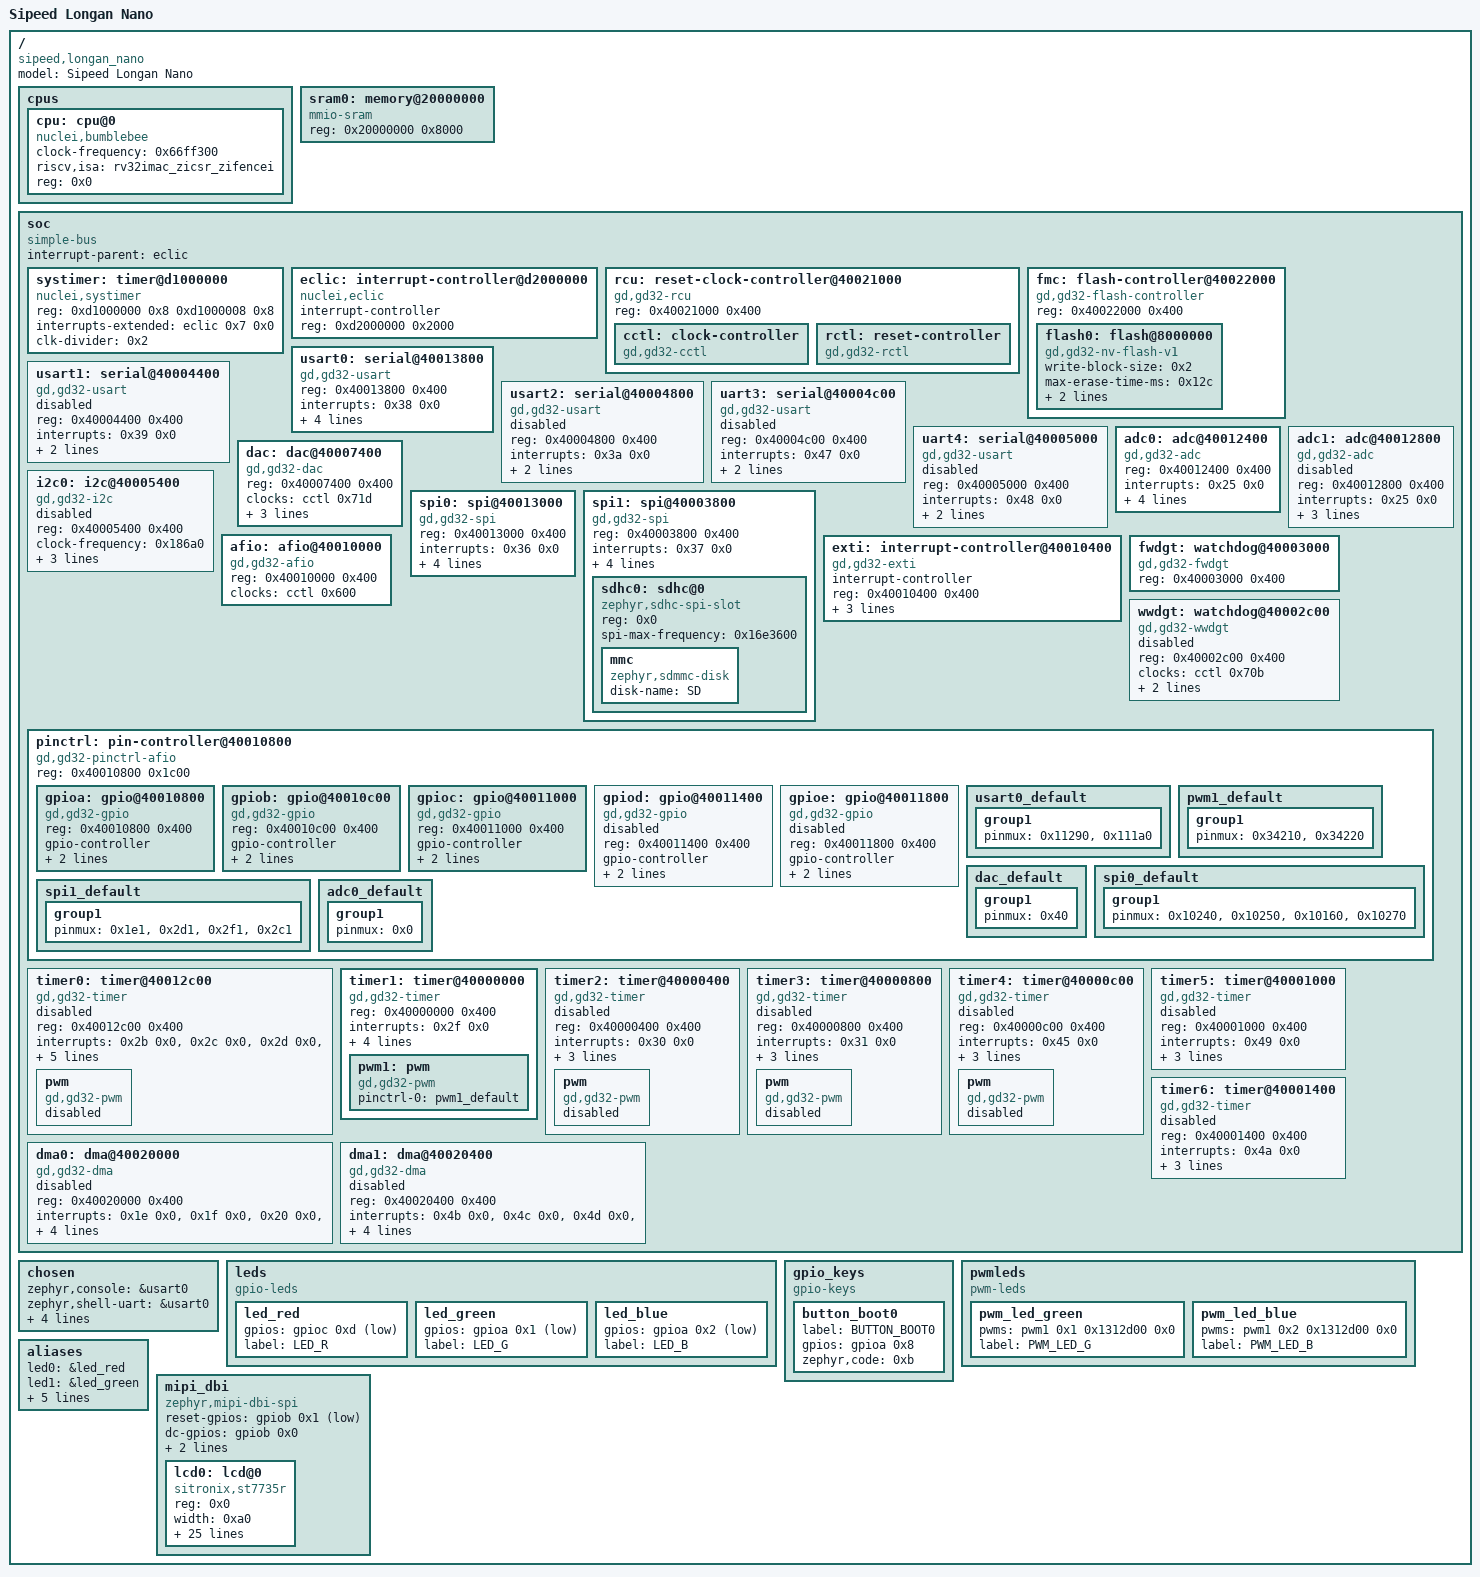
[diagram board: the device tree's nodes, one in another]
/dts-v1/;

/* node '/' defined in zephyr/dts/riscv/gd/gd32vf103.dtsi:16 */
/ {
	#address-cells = < 0x1 >;          /* in zephyr/dts/riscv/gd/gd32vf103.dtsi:17 */
	#size-cells = < 0x1 >;             /* in zephyr/dts/riscv/gd/gd32vf103.dtsi:18 */
	model = "Sipeed Longan Nano";      /* in zephyr/boards/sipeed/longan_nano/longan_nano.dts:13 */
	compatible = "sipeed,longan_nano"; /* in zephyr/boards/sipeed/longan_nano/longan_nano.dts:14 */

	/* node '/cpus' defined in zephyr/dts/riscv/gd/gd32vf103.dtsi:20 */
	cpus {
		#address-cells = < 0x1 >; /* in zephyr/dts/riscv/gd/gd32vf103.dtsi:21 */
		#size-cells = < 0x0 >;    /* in zephyr/dts/riscv/gd/gd32vf103.dtsi:22 */

		/* node '/cpus/cpu@0' defined in zephyr/dts/riscv/gd/gd32vf103.dtsi:24 */
		cpu: cpu@0 {
			clock-frequency = < 0x66ff300 >;       /* in zephyr/dts/riscv/gd/gd32vf103.dtsi:25 */
			compatible = "nuclei,bumblebee",
			             "riscv";                  /* in zephyr/dts/riscv/gd/gd32vf103.dtsi:26 */
			riscv,isa = "rv32imac_zicsr_zifencei"; /* in zephyr/dts/riscv/gd/gd32vf103.dtsi:27 */
			reg = < 0x0 >;                         /* in zephyr/dts/riscv/gd/gd32vf103.dtsi:28 */
		};
	};

	/* node '/memory@20000000' defined in zephyr/dts/riscv/gd/gd32vf103.dtsi:32 */
	sram0: memory@20000000 {
		compatible = "mmio-sram";    /* in zephyr/dts/riscv/gd/gd32vf103.dtsi:33 */
		reg = < 0x20000000 0x8000 >; /* in zephyr/dts/riscv/gd/gd32vf103Xb.dtsi:11 */
	};

	/* node '/soc' defined in zephyr/dts/riscv/gd/gd32vf103.dtsi:36 */
	soc {
		#address-cells = < 0x1 >;      /* in zephyr/dts/riscv/gd/gd32vf103.dtsi:37 */
		#size-cells = < 0x1 >;         /* in zephyr/dts/riscv/gd/gd32vf103.dtsi:38 */
		compatible = "simple-bus";     /* in zephyr/dts/riscv/gd/gd32vf103.dtsi:39 */
		interrupt-parent = < &eclic >; /* in zephyr/dts/riscv/gd/gd32vf103.dtsi:40 */
		ranges;                        /* in zephyr/dts/riscv/gd/gd32vf103.dtsi:41 */

		/* node '/soc/timer@d1000000' defined in zephyr/dts/riscv/gd/gd32vf103.dtsi:43 */
		systimer: timer@d1000000 {
			compatible = "nuclei,systimer",
			             "riscv,machine-timer";       /* in zephyr/dts/riscv/gd/gd32vf103.dtsi:44 */
			reg = < 0xd1000000 0x8 0xd1000008 0x8 >;  /* in zephyr/dts/riscv/gd/gd32vf103.dtsi:45 */
			reg-names = "mtime",
			            "mtimecmp";                   /* in zephyr/dts/riscv/gd/gd32vf103.dtsi:46 */
			interrupts-extended = < &eclic 0x7 0x0 >; /* in zephyr/dts/riscv/gd/gd32vf103.dtsi:47 */
			clk-divider = < 0x2 >;                    /* in zephyr/dts/riscv/gd/gd32vf103.dtsi:48 */
		};

		/* node '/soc/interrupt-controller@d2000000' defined in zephyr/dts/riscv/gd/gd32vf103.dtsi:51 */
		eclic: interrupt-controller@d2000000 {
			compatible = "nuclei,eclic"; /* in zephyr/dts/riscv/gd/gd32vf103.dtsi:52 */
			#address-cells = < 0x0 >;    /* in zephyr/dts/riscv/gd/gd32vf103.dtsi:53 */
			#interrupt-cells = < 0x2 >;  /* in zephyr/dts/riscv/gd/gd32vf103.dtsi:54 */
			interrupt-controller;        /* in zephyr/dts/riscv/gd/gd32vf103.dtsi:55 */
			reg = < 0xd2000000 0x2000 >; /* in zephyr/dts/riscv/gd/gd32vf103.dtsi:56 */
			phandle = < 0x1 >;           /* in zephyr/dts/riscv/gd/gd32vf103.dtsi:40 */
		};

		/* node '/soc/reset-clock-controller@40021000' defined in zephyr/dts/riscv/gd/gd32vf103.dtsi:59 */
		rcu: reset-clock-controller@40021000 {
			compatible = "gd,gd32-rcu"; /* in zephyr/dts/riscv/gd/gd32vf103.dtsi:60 */
			reg = < 0x40021000 0x400 >; /* in zephyr/dts/riscv/gd/gd32vf103.dtsi:61 */
			status = "okay";            /* in zephyr/dts/riscv/gd/gd32vf103.dtsi:62 */

			/* node '/soc/reset-clock-controller@40021000/clock-controller' defined in zephyr/dts/riscv/gd/gd32vf103.dtsi:64 */
			cctl: clock-controller {
				compatible = "gd,gd32-cctl"; /* in zephyr/dts/riscv/gd/gd32vf103.dtsi:65 */
				#clock-cells = < 0x1 >;      /* in zephyr/dts/riscv/gd/gd32vf103.dtsi:66 */
				status = "okay";             /* in zephyr/dts/riscv/gd/gd32vf103.dtsi:67 */
				phandle = < 0x2 >;           /* in zephyr/dts/riscv/gd/gd32vf103.dtsi:95 */
			};

			/* node '/soc/reset-clock-controller@40021000/reset-controller' defined in zephyr/dts/riscv/gd/gd32vf103.dtsi:70 */
			rctl: reset-controller {
				compatible = "gd,gd32-rctl"; /* in zephyr/dts/riscv/gd/gd32vf103.dtsi:71 */
				#reset-cells = < 0x1 >;      /* in zephyr/dts/riscv/gd/gd32vf103.dtsi:72 */
				status = "okay";             /* in zephyr/dts/riscv/gd/gd32vf103.dtsi:73 */
				phandle = < 0x3 >;           /* in zephyr/dts/riscv/gd/gd32vf103.dtsi:96 */
			};
		};

		/* node '/soc/flash-controller@40022000' defined in zephyr/dts/riscv/gd/gd32vf103.dtsi:77 */
		fmc: flash-controller@40022000 {
			compatible = "gd,gd32-flash-controller"; /* in zephyr/dts/riscv/gd/gd32vf103.dtsi:78 */
			reg = < 0x40022000 0x400 >;              /* in zephyr/dts/riscv/gd/gd32vf103.dtsi:79 */
			#address-cells = < 0x1 >;                /* in zephyr/dts/riscv/gd/gd32vf103.dtsi:80 */
			#size-cells = < 0x1 >;                   /* in zephyr/dts/riscv/gd/gd32vf103.dtsi:81 */

			/* node '/soc/flash-controller@40022000/flash@8000000' defined in zephyr/dts/riscv/gd/gd32vf103.dtsi:83 */
			flash0: flash@8000000 {
				compatible = "gd,gd32-nv-flash-v1",
				             "soc-nv-flash";        /* in zephyr/dts/riscv/gd/gd32vf103.dtsi:84 */
				write-block-size = < 0x2 >;         /* in zephyr/dts/riscv/gd/gd32vf103.dtsi:85 */
				max-erase-time-ms = < 0x12c >;      /* in zephyr/dts/riscv/gd/gd32vf103.dtsi:86 */
				page-size = < 0x400 >;              /* in zephyr/dts/riscv/gd/gd32vf103.dtsi:87 */
				reg = < 0x8000000 0x20000 >;        /* in zephyr/dts/riscv/gd/gd32vf103Xb.dtsi:15 */
			};
		};

		/* node '/soc/serial@40013800' defined in zephyr/dts/riscv/gd/gd32vf103.dtsi:91 */
		usart0: serial@40013800 {
			compatible = "gd,gd32-usart";    /* in zephyr/dts/riscv/gd/gd32vf103.dtsi:92 */
			reg = < 0x40013800 0x400 >;      /* in zephyr/dts/riscv/gd/gd32vf103.dtsi:93 */
			interrupts = < 0x38 0x0 >;       /* in zephyr/dts/riscv/gd/gd32vf103.dtsi:94 */
			clocks = < &cctl 0x60e >;        /* in zephyr/dts/riscv/gd/gd32vf103.dtsi:95 */
			resets = < &rctl 0x30e >;        /* in zephyr/dts/riscv/gd/gd32vf103.dtsi:96 */
			status = "okay";                 /* in zephyr/boards/sipeed/longan_nano/longan_nano-common.dtsi:133 */
			current-speed = < 0x1c200 >;     /* in zephyr/boards/sipeed/longan_nano/longan_nano-common.dtsi:134 */
			pinctrl-0 = < &usart0_default >; /* in zephyr/boards/sipeed/longan_nano/longan_nano-common.dtsi:135 */
			pinctrl-names = "default";       /* in zephyr/boards/sipeed/longan_nano/longan_nano-common.dtsi:136 */
		};

		/* node '/soc/serial@40004400' defined in zephyr/dts/riscv/gd/gd32vf103.dtsi:100 */
		usart1: serial@40004400 {
			compatible = "gd,gd32-usart"; /* in zephyr/dts/riscv/gd/gd32vf103.dtsi:101 */
			reg = < 0x40004400 0x400 >;   /* in zephyr/dts/riscv/gd/gd32vf103.dtsi:102 */
			interrupts = < 0x39 0x0 >;    /* in zephyr/dts/riscv/gd/gd32vf103.dtsi:103 */
			clocks = < &cctl 0x711 >;     /* in zephyr/dts/riscv/gd/gd32vf103.dtsi:104 */
			resets = < &rctl 0x411 >;     /* in zephyr/dts/riscv/gd/gd32vf103.dtsi:105 */
			status = "disabled";          /* in zephyr/dts/riscv/gd/gd32vf103.dtsi:106 */
		};

		/* node '/soc/serial@40004800' defined in zephyr/dts/riscv/gd/gd32vf103.dtsi:109 */
		usart2: serial@40004800 {
			compatible = "gd,gd32-usart"; /* in zephyr/dts/riscv/gd/gd32vf103.dtsi:110 */
			reg = < 0x40004800 0x400 >;   /* in zephyr/dts/riscv/gd/gd32vf103.dtsi:111 */
			interrupts = < 0x3a 0x0 >;    /* in zephyr/dts/riscv/gd/gd32vf103.dtsi:112 */
			clocks = < &cctl 0x712 >;     /* in zephyr/dts/riscv/gd/gd32vf103.dtsi:113 */
			resets = < &rctl 0x412 >;     /* in zephyr/dts/riscv/gd/gd32vf103.dtsi:114 */
			status = "disabled";          /* in zephyr/dts/riscv/gd/gd32vf103.dtsi:115 */
		};

		/* node '/soc/serial@40004c00' defined in zephyr/dts/riscv/gd/gd32vf103.dtsi:118 */
		uart3: serial@40004c00 {
			compatible = "gd,gd32-usart"; /* in zephyr/dts/riscv/gd/gd32vf103.dtsi:119 */
			reg = < 0x40004c00 0x400 >;   /* in zephyr/dts/riscv/gd/gd32vf103.dtsi:120 */
			interrupts = < 0x47 0x0 >;    /* in zephyr/dts/riscv/gd/gd32vf103.dtsi:121 */
			clocks = < &cctl 0x713 >;     /* in zephyr/dts/riscv/gd/gd32vf103.dtsi:122 */
			resets = < &rctl 0x413 >;     /* in zephyr/dts/riscv/gd/gd32vf103.dtsi:123 */
			status = "disabled";          /* in zephyr/dts/riscv/gd/gd32vf103.dtsi:124 */
		};

		/* node '/soc/serial@40005000' defined in zephyr/dts/riscv/gd/gd32vf103.dtsi:127 */
		uart4: serial@40005000 {
			compatible = "gd,gd32-usart"; /* in zephyr/dts/riscv/gd/gd32vf103.dtsi:128 */
			reg = < 0x40005000 0x400 >;   /* in zephyr/dts/riscv/gd/gd32vf103.dtsi:129 */
			interrupts = < 0x48 0x0 >;    /* in zephyr/dts/riscv/gd/gd32vf103.dtsi:130 */
			clocks = < &cctl 0x714 >;     /* in zephyr/dts/riscv/gd/gd32vf103.dtsi:131 */
			resets = < &rctl 0x414 >;     /* in zephyr/dts/riscv/gd/gd32vf103.dtsi:132 */
			status = "disabled";          /* in zephyr/dts/riscv/gd/gd32vf103.dtsi:133 */
		};

		/* node '/soc/adc@40012400' defined in zephyr/dts/riscv/gd/gd32vf103.dtsi:136 */
		adc0: adc@40012400 {
			compatible = "gd,gd32-adc";    /* in zephyr/dts/riscv/gd/gd32vf103.dtsi:137 */
			reg = < 0x40012400 0x400 >;    /* in zephyr/dts/riscv/gd/gd32vf103.dtsi:138 */
			interrupts = < 0x25 0x0 >;     /* in zephyr/dts/riscv/gd/gd32vf103.dtsi:139 */
			clocks = < &cctl 0x609 >;      /* in zephyr/dts/riscv/gd/gd32vf103.dtsi:140 */
			resets = < &rctl 0x309 >;      /* in zephyr/dts/riscv/gd/gd32vf103.dtsi:141 */
			channels = < 0x10 >;           /* in zephyr/dts/riscv/gd/gd32vf103.dtsi:142 */
			#io-channel-cells = < 0x1 >;   /* in zephyr/dts/riscv/gd/gd32vf103.dtsi:144 */
			status = "okay";               /* in zephyr/boards/sipeed/longan_nano/longan_nano-common.dtsi:186 */
			pinctrl-0 = < &adc0_default >; /* in zephyr/boards/sipeed/longan_nano/longan_nano-common.dtsi:187 */
			pinctrl-names = "default";     /* in zephyr/boards/sipeed/longan_nano/longan_nano-common.dtsi:188 */
		};

		/* node '/soc/adc@40012800' defined in zephyr/dts/riscv/gd/gd32vf103.dtsi:147 */
		adc1: adc@40012800 {
			compatible = "gd,gd32-adc";  /* in zephyr/dts/riscv/gd/gd32vf103.dtsi:148 */
			reg = < 0x40012800 0x400 >;  /* in zephyr/dts/riscv/gd/gd32vf103.dtsi:149 */
			interrupts = < 0x25 0x0 >;   /* in zephyr/dts/riscv/gd/gd32vf103.dtsi:150 */
			clocks = < &cctl 0x60a >;    /* in zephyr/dts/riscv/gd/gd32vf103.dtsi:151 */
			resets = < &rctl 0x30a >;    /* in zephyr/dts/riscv/gd/gd32vf103.dtsi:152 */
			channels = < 0x10 >;         /* in zephyr/dts/riscv/gd/gd32vf103.dtsi:153 */
			status = "disabled";         /* in zephyr/dts/riscv/gd/gd32vf103.dtsi:154 */
			#io-channel-cells = < 0x1 >; /* in zephyr/dts/riscv/gd/gd32vf103.dtsi:155 */
		};

		/* node '/soc/dac@40007400' defined in zephyr/dts/riscv/gd/gd32vf103.dtsi:158 */
		dac: dac@40007400 {
			compatible = "gd,gd32-dac";   /* in zephyr/dts/riscv/gd/gd32vf103.dtsi:159 */
			reg = < 0x40007400 0x400 >;   /* in zephyr/dts/riscv/gd/gd32vf103.dtsi:160 */
			clocks = < &cctl 0x71d >;     /* in zephyr/dts/riscv/gd/gd32vf103.dtsi:161 */
			resets = < &rctl 0x41d >;     /* in zephyr/dts/riscv/gd/gd32vf103.dtsi:162 */
			num-channels = < 0x2 >;       /* in zephyr/dts/riscv/gd/gd32vf103.dtsi:163 */
			#io-channel-cells = < 0x1 >;  /* in zephyr/dts/riscv/gd/gd32vf103.dtsi:165 */
			status = "okay";              /* in zephyr/boards/sipeed/longan_nano/longan_nano-common.dtsi:151 */
			pinctrl-0 = < &dac_default >; /* in zephyr/boards/sipeed/longan_nano/longan_nano-common.dtsi:152 */
			pinctrl-names = "default";    /* in zephyr/boards/sipeed/longan_nano/longan_nano-common.dtsi:153 */
		};

		/* node '/soc/i2c@40005400' defined in zephyr/dts/riscv/gd/gd32vf103.dtsi:168 */
		i2c0: i2c@40005400 {
			compatible = "gd,gd32-i2c";    /* in zephyr/dts/riscv/gd/gd32vf103.dtsi:169 */
			reg = < 0x40005400 0x400 >;    /* in zephyr/dts/riscv/gd/gd32vf103.dtsi:170 */
			#address-cells = < 0x1 >;      /* in zephyr/dts/riscv/gd/gd32vf103.dtsi:171 */
			#size-cells = < 0x0 >;         /* in zephyr/dts/riscv/gd/gd32vf103.dtsi:172 */
			clock-frequency = < 0x186a0 >; /* in zephyr/dts/riscv/gd/gd32vf103.dtsi:173 */
			interrupts = < 0x32 0x0 >,
			             < 0x33 0x0 >;     /* in zephyr/dts/riscv/gd/gd32vf103.dtsi:174 */
			interrupt-names = "event",
			                  "error";     /* in zephyr/dts/riscv/gd/gd32vf103.dtsi:175 */
			clocks = < &cctl 0x715 >;      /* in zephyr/dts/riscv/gd/gd32vf103.dtsi:176 */
			resets = < &rctl 0x415 >;      /* in zephyr/dts/riscv/gd/gd32vf103.dtsi:177 */
			status = "disabled";           /* in zephyr/dts/riscv/gd/gd32vf103.dtsi:178 */
		};

		/* node '/soc/spi@40013000' defined in zephyr/dts/riscv/gd/gd32vf103.dtsi:181 */
		spi0: spi@40013000 {
			compatible = "gd,gd32-spi";    /* in zephyr/dts/riscv/gd/gd32vf103.dtsi:182 */
			reg = < 0x40013000 0x400 >;    /* in zephyr/dts/riscv/gd/gd32vf103.dtsi:183 */
			interrupts = < 0x36 0x0 >;     /* in zephyr/dts/riscv/gd/gd32vf103.dtsi:184 */
			clocks = < &cctl 0x60c >;      /* in zephyr/dts/riscv/gd/gd32vf103.dtsi:185 */
			resets = < &rctl 0x30c >;      /* in zephyr/dts/riscv/gd/gd32vf103.dtsi:186 */
			#address-cells = < 0x1 >;      /* in zephyr/dts/riscv/gd/gd32vf103.dtsi:188 */
			#size-cells = < 0x0 >;         /* in zephyr/dts/riscv/gd/gd32vf103.dtsi:189 */
			status = "okay";               /* in zephyr/boards/sipeed/longan_nano/longan_nano-common.dtsi:157 */
			pinctrl-0 = < &spi0_default >; /* in zephyr/boards/sipeed/longan_nano/longan_nano-common.dtsi:158 */
			pinctrl-names = "default";     /* in zephyr/boards/sipeed/longan_nano/longan_nano-common.dtsi:159 */
			cs-gpios = < &gpiob 0x2 0x1 >; /* in zephyr/boards/sipeed/longan_nano/longan_nano-common.dtsi:161 */
			phandle = < 0xe >;             /* in zephyr/boards/sipeed/longan_nano/longan_nano-common.dtsi:79 */
		};

		/* node '/soc/spi@40003800' defined in zephyr/dts/riscv/gd/gd32vf103.dtsi:192 */
		spi1: spi@40003800 {
			compatible = "gd,gd32-spi";    /* in zephyr/dts/riscv/gd/gd32vf103.dtsi:193 */
			reg = < 0x40003800 0x400 >;    /* in zephyr/dts/riscv/gd/gd32vf103.dtsi:194 */
			interrupts = < 0x37 0x0 >;     /* in zephyr/dts/riscv/gd/gd32vf103.dtsi:195 */
			clocks = < &cctl 0x70e >;      /* in zephyr/dts/riscv/gd/gd32vf103.dtsi:196 */
			resets = < &rctl 0x40e >;      /* in zephyr/dts/riscv/gd/gd32vf103.dtsi:197 */
			#address-cells = < 0x1 >;      /* in zephyr/dts/riscv/gd/gd32vf103.dtsi:199 */
			#size-cells = < 0x0 >;         /* in zephyr/dts/riscv/gd/gd32vf103.dtsi:200 */
			status = "okay";               /* in zephyr/boards/sipeed/longan_nano/longan_nano-common.dtsi:165 */
			pinctrl-0 = < &spi1_default >; /* in zephyr/boards/sipeed/longan_nano/longan_nano-common.dtsi:166 */
			pinctrl-names = "default";     /* in zephyr/boards/sipeed/longan_nano/longan_nano-common.dtsi:167 */
			cs-gpios = < &gpiob 0xc 0x1 >; /* in zephyr/boards/sipeed/longan_nano/longan_nano-common.dtsi:169 */

			/* node '/soc/spi@40003800/sdhc@0' defined in zephyr/boards/sipeed/longan_nano/longan_nano-common.dtsi:171 */
			sdhc0: sdhc@0 {
				compatible = "zephyr,sdhc-spi-slot"; /* in zephyr/boards/sipeed/longan_nano/longan_nano-common.dtsi:172 */
				reg = < 0x0 >;                       /* in zephyr/boards/sipeed/longan_nano/longan_nano-common.dtsi:173 */
				status = "okay";                     /* in zephyr/boards/sipeed/longan_nano/longan_nano-common.dtsi:174 */
				spi-max-frequency = < 0x16e3600 >;   /* in zephyr/boards/sipeed/longan_nano/longan_nano-common.dtsi:175 */

				/* node '/soc/spi@40003800/sdhc@0/mmc' defined in zephyr/boards/sipeed/longan_nano/longan_nano-common.dtsi:177 */
				mmc {
					compatible = "zephyr,sdmmc-disk"; /* in zephyr/boards/sipeed/longan_nano/longan_nano-common.dtsi:178 */
					disk-name = "SD";                 /* in zephyr/boards/sipeed/longan_nano/longan_nano-common.dtsi:179 */
					status = "okay";                  /* in zephyr/boards/sipeed/longan_nano/longan_nano-common.dtsi:180 */
				};
			};
		};

		/* node '/soc/afio@40010000' defined in zephyr/dts/riscv/gd/gd32vf103.dtsi:203 */
		afio: afio@40010000 {
			compatible = "gd,gd32-afio"; /* in zephyr/dts/riscv/gd/gd32vf103.dtsi:204 */
			reg = < 0x40010000 0x400 >;  /* in zephyr/dts/riscv/gd/gd32vf103.dtsi:205 */
			clocks = < &cctl 0x600 >;    /* in zephyr/dts/riscv/gd/gd32vf103.dtsi:206 */
			status = "okay";             /* in zephyr/dts/riscv/gd/gd32vf103.dtsi:207 */
		};

		/* node '/soc/interrupt-controller@40010400' defined in zephyr/dts/riscv/gd/gd32vf103.dtsi:210 */
		exti: interrupt-controller@40010400 {
			compatible = "gd,gd32-exti";   /* in zephyr/dts/riscv/gd/gd32vf103.dtsi:211 */
			#address-cells = < 0x0 >;      /* in zephyr/dts/riscv/gd/gd32vf103.dtsi:212 */
			interrupt-controller;          /* in zephyr/dts/riscv/gd/gd32vf103.dtsi:213 */
			#interrupt-cells = < 0x1 >;    /* in zephyr/dts/riscv/gd/gd32vf103.dtsi:214 */
			reg = < 0x40010400 0x400 >;    /* in zephyr/dts/riscv/gd/gd32vf103.dtsi:215 */
			num-lines = < 0x13 >;          /* in zephyr/dts/riscv/gd/gd32vf103.dtsi:216 */
			interrupts = < 0x19 0x0 >,
			             < 0x1a 0x0 >,
			             < 0x1b 0x0 >,
			             < 0x1c 0x0 >,
			             < 0x1d 0x0 >,
			             < 0x2a 0x0 >,
			             < 0x3b 0x0 >;     /* in zephyr/dts/riscv/gd/gd32vf103.dtsi:217 */
			interrupt-names = "line0",
			                  "line1",
			                  "line2",
			                  "line3",
			                  "line4",
			                  "line5-9",
			                  "line10-15"; /* in zephyr/dts/riscv/gd/gd32vf103.dtsi:219 */
			status = "okay";               /* in zephyr/dts/riscv/gd/gd32vf103.dtsi:221 */
		};

		/* node '/soc/watchdog@40003000' defined in zephyr/dts/riscv/gd/gd32vf103.dtsi:224 */
		fwdgt: watchdog@40003000 {
			compatible = "gd,gd32-fwdgt"; /* in zephyr/dts/riscv/gd/gd32vf103.dtsi:225 */
			reg = < 0x40003000 0x400 >;   /* in zephyr/dts/riscv/gd/gd32vf103.dtsi:226 */
			status = "okay";              /* in zephyr/boards/sipeed/longan_nano/longan_nano-common.dtsi:192 */
		};

		/* node '/soc/watchdog@40002c00' defined in zephyr/dts/riscv/gd/gd32vf103.dtsi:230 */
		wwdgt: watchdog@40002c00 {
			compatible = "gd,gd32-wwdgt"; /* in zephyr/dts/riscv/gd/gd32vf103.dtsi:231 */
			reg = < 0x40002c00 0x400 >;   /* in zephyr/dts/riscv/gd/gd32vf103.dtsi:232 */
			clocks = < &cctl 0x70b >;     /* in zephyr/dts/riscv/gd/gd32vf103.dtsi:233 */
			resets = < &rctl 0x40b >;     /* in zephyr/dts/riscv/gd/gd32vf103.dtsi:234 */
			interrupts = < 0x0 0x0 >;     /* in zephyr/dts/riscv/gd/gd32vf103.dtsi:235 */
			status = "disabled";          /* in zephyr/dts/riscv/gd/gd32vf103.dtsi:236 */
		};

		/* node '/soc/pin-controller@40010800' defined in zephyr/dts/riscv/gd/gd32vf103.dtsi:239 */
		pinctrl: pin-controller@40010800 {
			compatible = "gd,gd32-pinctrl-afio"; /* in zephyr/dts/riscv/gd/gd32vf103.dtsi:240 */
			reg = < 0x40010800 0x1c00 >;         /* in zephyr/dts/riscv/gd/gd32vf103.dtsi:241 */
			#address-cells = < 0x1 >;            /* in zephyr/dts/riscv/gd/gd32vf103.dtsi:242 */
			#size-cells = < 0x1 >;               /* in zephyr/dts/riscv/gd/gd32vf103.dtsi:243 */
			status = "okay";                     /* in zephyr/dts/riscv/gd/gd32vf103.dtsi:244 */

			/* node '/soc/pin-controller@40010800/gpio@40010800' defined in zephyr/dts/riscv/gd/gd32vf103.dtsi:246 */
			gpioa: gpio@40010800 {
				compatible = "gd,gd32-gpio"; /* in zephyr/dts/riscv/gd/gd32vf103.dtsi:247 */
				reg = < 0x40010800 0x400 >;  /* in zephyr/dts/riscv/gd/gd32vf103.dtsi:248 */
				gpio-controller;             /* in zephyr/dts/riscv/gd/gd32vf103.dtsi:249 */
				#gpio-cells = < 0x2 >;       /* in zephyr/dts/riscv/gd/gd32vf103.dtsi:250 */
				clocks = < &cctl 0x602 >;    /* in zephyr/dts/riscv/gd/gd32vf103.dtsi:251 */
				resets = < &rctl 0x302 >;    /* in zephyr/dts/riscv/gd/gd32vf103.dtsi:252 */
				status = "okay";             /* in zephyr/boards/sipeed/longan_nano/longan_nano-common.dtsi:121 */
				phandle = < 0xc >;           /* in zephyr/boards/sipeed/longan_nano/longan_nano-common.dtsi:29 */
			};

			/* node '/soc/pin-controller@40010800/gpio@40010c00' defined in zephyr/dts/riscv/gd/gd32vf103.dtsi:256 */
			gpiob: gpio@40010c00 {
				compatible = "gd,gd32-gpio"; /* in zephyr/dts/riscv/gd/gd32vf103.dtsi:257 */
				reg = < 0x40010c00 0x400 >;  /* in zephyr/dts/riscv/gd/gd32vf103.dtsi:258 */
				gpio-controller;             /* in zephyr/dts/riscv/gd/gd32vf103.dtsi:259 */
				#gpio-cells = < 0x2 >;       /* in zephyr/dts/riscv/gd/gd32vf103.dtsi:260 */
				clocks = < &cctl 0x603 >;    /* in zephyr/dts/riscv/gd/gd32vf103.dtsi:261 */
				resets = < &rctl 0x303 >;    /* in zephyr/dts/riscv/gd/gd32vf103.dtsi:262 */
				status = "okay";             /* in zephyr/boards/sipeed/longan_nano/longan_nano-common.dtsi:125 */
				phandle = < 0x8 >;           /* in zephyr/boards/sipeed/longan_nano/longan_nano-common.dtsi:161 */
			};

			/* node '/soc/pin-controller@40010800/gpio@40011000' defined in zephyr/dts/riscv/gd/gd32vf103.dtsi:266 */
			gpioc: gpio@40011000 {
				compatible = "gd,gd32-gpio"; /* in zephyr/dts/riscv/gd/gd32vf103.dtsi:267 */
				reg = < 0x40011000 0x400 >;  /* in zephyr/dts/riscv/gd/gd32vf103.dtsi:268 */
				gpio-controller;             /* in zephyr/dts/riscv/gd/gd32vf103.dtsi:269 */
				#gpio-cells = < 0x2 >;       /* in zephyr/dts/riscv/gd/gd32vf103.dtsi:270 */
				clocks = < &cctl 0x604 >;    /* in zephyr/dts/riscv/gd/gd32vf103.dtsi:271 */
				resets = < &rctl 0x304 >;    /* in zephyr/dts/riscv/gd/gd32vf103.dtsi:272 */
				status = "okay";             /* in zephyr/boards/sipeed/longan_nano/longan_nano-common.dtsi:129 */
				phandle = < 0xb >;           /* in zephyr/boards/sipeed/longan_nano/longan_nano-common.dtsi:24 */
			};

			/* node '/soc/pin-controller@40010800/gpio@40011400' defined in zephyr/dts/riscv/gd/gd32vf103.dtsi:276 */
			gpiod: gpio@40011400 {
				compatible = "gd,gd32-gpio"; /* in zephyr/dts/riscv/gd/gd32vf103.dtsi:277 */
				reg = < 0x40011400 0x400 >;  /* in zephyr/dts/riscv/gd/gd32vf103.dtsi:278 */
				gpio-controller;             /* in zephyr/dts/riscv/gd/gd32vf103.dtsi:279 */
				#gpio-cells = < 0x2 >;       /* in zephyr/dts/riscv/gd/gd32vf103.dtsi:280 */
				clocks = < &cctl 0x605 >;    /* in zephyr/dts/riscv/gd/gd32vf103.dtsi:281 */
				resets = < &rctl 0x305 >;    /* in zephyr/dts/riscv/gd/gd32vf103.dtsi:282 */
				status = "disabled";         /* in zephyr/dts/riscv/gd/gd32vf103.dtsi:283 */
			};

			/* node '/soc/pin-controller@40010800/gpio@40011800' defined in zephyr/dts/riscv/gd/gd32vf103.dtsi:286 */
			gpioe: gpio@40011800 {
				compatible = "gd,gd32-gpio"; /* in zephyr/dts/riscv/gd/gd32vf103.dtsi:287 */
				reg = < 0x40011800 0x400 >;  /* in zephyr/dts/riscv/gd/gd32vf103.dtsi:288 */
				gpio-controller;             /* in zephyr/dts/riscv/gd/gd32vf103.dtsi:289 */
				#gpio-cells = < 0x2 >;       /* in zephyr/dts/riscv/gd/gd32vf103.dtsi:290 */
				clocks = < &cctl 0x606 >;    /* in zephyr/dts/riscv/gd/gd32vf103.dtsi:291 */
				resets = < &rctl 0x306 >;    /* in zephyr/dts/riscv/gd/gd32vf103.dtsi:292 */
				status = "disabled";         /* in zephyr/dts/riscv/gd/gd32vf103.dtsi:293 */
			};

			/* node '/soc/pin-controller@40010800/usart0_default' defined in zephyr/boards/sipeed/longan_nano/longan_nano-pinctrl.dtsi:9 */
			usart0_default: usart0_default {
				phandle = < 0x4 >; /* in zephyr/boards/sipeed/longan_nano/longan_nano-common.dtsi:135 */

				/* node '/soc/pin-controller@40010800/usart0_default/group1' defined in zephyr/boards/sipeed/longan_nano/longan_nano-pinctrl.dtsi:10 */
				group1 {
					pinmux = < 0x11290 >,
					         < 0x111a0 >; /* in zephyr/boards/sipeed/longan_nano/longan_nano-pinctrl.dtsi:11 */
				};
			};

			/* node '/soc/pin-controller@40010800/pwm1_default' defined in zephyr/boards/sipeed/longan_nano/longan_nano-pinctrl.dtsi:15 */
			pwm1_default: pwm1_default {
				phandle = < 0xa >; /* in zephyr/boards/sipeed/longan_nano/longan_nano-common.dtsi:145 */

				/* node '/soc/pin-controller@40010800/pwm1_default/group1' defined in zephyr/boards/sipeed/longan_nano/longan_nano-pinctrl.dtsi:16 */
				group1 {
					pinmux = < 0x34210 >,
					         < 0x34220 >; /* in zephyr/boards/sipeed/longan_nano/longan_nano-pinctrl.dtsi:17 */
				};
			};

			/* node '/soc/pin-controller@40010800/dac_default' defined in zephyr/boards/sipeed/longan_nano/longan_nano-pinctrl.dtsi:21 */
			dac_default: dac_default {
				phandle = < 0x6 >; /* in zephyr/boards/sipeed/longan_nano/longan_nano-common.dtsi:152 */

				/* node '/soc/pin-controller@40010800/dac_default/group1' defined in zephyr/boards/sipeed/longan_nano/longan_nano-pinctrl.dtsi:22 */
				group1 {
					pinmux = < 0x40 >; /* in zephyr/boards/sipeed/longan_nano/longan_nano-pinctrl.dtsi:23 */
				};
			};

			/* node '/soc/pin-controller@40010800/spi0_default' defined in zephyr/boards/sipeed/longan_nano/longan_nano-pinctrl.dtsi:27 */
			spi0_default: spi0_default {
				phandle = < 0x7 >; /* in zephyr/boards/sipeed/longan_nano/longan_nano-common.dtsi:158 */

				/* node '/soc/pin-controller@40010800/spi0_default/group1' defined in zephyr/boards/sipeed/longan_nano/longan_nano-pinctrl.dtsi:28 */
				group1 {
					pinmux = < 0x10240 >,
					         < 0x10250 >,
					         < 0x10160 >,
					         < 0x10270 >; /* in zephyr/boards/sipeed/longan_nano/longan_nano-pinctrl.dtsi:29 */
				};
			};

			/* node '/soc/pin-controller@40010800/spi1_default' defined in zephyr/boards/sipeed/longan_nano/longan_nano-pinctrl.dtsi:34 */
			spi1_default: spi1_default {
				phandle = < 0x9 >; /* in zephyr/boards/sipeed/longan_nano/longan_nano-common.dtsi:166 */

				/* node '/soc/pin-controller@40010800/spi1_default/group1' defined in zephyr/boards/sipeed/longan_nano/longan_nano-pinctrl.dtsi:35 */
				group1 {
					pinmux = < 0x1e1 >,
					         < 0x2d1 >,
					         < 0x2f1 >,
					         < 0x2c1 >; /* in zephyr/boards/sipeed/longan_nano/longan_nano-pinctrl.dtsi:36 */
				};
			};

			/* node '/soc/pin-controller@40010800/adc0_default' defined in zephyr/boards/sipeed/longan_nano/longan_nano-pinctrl.dtsi:41 */
			adc0_default: adc0_default {
				phandle = < 0x5 >; /* in zephyr/boards/sipeed/longan_nano/longan_nano-common.dtsi:187 */

				/* node '/soc/pin-controller@40010800/adc0_default/group1' defined in zephyr/boards/sipeed/longan_nano/longan_nano-pinctrl.dtsi:42 */
				group1 {
					pinmux = < 0x0 >; /* in zephyr/boards/sipeed/longan_nano/longan_nano-pinctrl.dtsi:43 */
				};
			};
		};

		/* node '/soc/timer@40012c00' defined in zephyr/dts/riscv/gd/gd32vf103.dtsi:297 */
		timer0: timer@40012c00 {
			compatible = "gd,gd32-timer"; /* in zephyr/dts/riscv/gd/gd32vf103.dtsi:298 */
			reg = < 0x40012c00 0x400 >;   /* in zephyr/dts/riscv/gd/gd32vf103.dtsi:299 */
			interrupts = < 0x2b 0x0 >,
			             < 0x2c 0x0 >,
			             < 0x2d 0x0 >,
			             < 0x2e 0x0 >;    /* in zephyr/dts/riscv/gd/gd32vf103.dtsi:300 */
			interrupt-names = "brk",
			                  "up",
			                  "trgcom",
			                  "cc";       /* in zephyr/dts/riscv/gd/gd32vf103.dtsi:301 */
			clocks = < &cctl 0x60b >;     /* in zephyr/dts/riscv/gd/gd32vf103.dtsi:302 */
			resets = < &rctl 0x30b >;     /* in zephyr/dts/riscv/gd/gd32vf103.dtsi:303 */
			is-advanced;                  /* in zephyr/dts/riscv/gd/gd32vf103.dtsi:304 */
			channels = < 0x4 >;           /* in zephyr/dts/riscv/gd/gd32vf103.dtsi:305 */
			status = "disabled";          /* in zephyr/dts/riscv/gd/gd32vf103.dtsi:306 */

			/* node '/soc/timer@40012c00/pwm' defined in zephyr/dts/riscv/gd/gd32vf103.dtsi:308 */
			pwm {
				compatible = "gd,gd32-pwm"; /* in zephyr/dts/riscv/gd/gd32vf103.dtsi:309 */
				status = "disabled";        /* in zephyr/dts/riscv/gd/gd32vf103.dtsi:310 */
				#pwm-cells = < 0x3 >;       /* in zephyr/dts/riscv/gd/gd32vf103.dtsi:311 */
			};
		};

		/* node '/soc/timer@40000000' defined in zephyr/dts/riscv/gd/gd32vf103.dtsi:315 */
		timer1: timer@40000000 {
			compatible = "gd,gd32-timer"; /* in zephyr/dts/riscv/gd/gd32vf103.dtsi:316 */
			reg = < 0x40000000 0x400 >;   /* in zephyr/dts/riscv/gd/gd32vf103.dtsi:317 */
			interrupts = < 0x2f 0x0 >;    /* in zephyr/dts/riscv/gd/gd32vf103.dtsi:318 */
			interrupt-names = "global";   /* in zephyr/dts/riscv/gd/gd32vf103.dtsi:319 */
			clocks = < &cctl 0x700 >;     /* in zephyr/dts/riscv/gd/gd32vf103.dtsi:320 */
			resets = < &rctl 0x400 >;     /* in zephyr/dts/riscv/gd/gd32vf103.dtsi:321 */
			channels = < 0x4 >;           /* in zephyr/dts/riscv/gd/gd32vf103.dtsi:322 */
			status = "okay";              /* in zephyr/boards/sipeed/longan_nano/longan_nano-common.dtsi:140 */
			prescaler = < 0x1000 >;       /* in zephyr/boards/sipeed/longan_nano/longan_nano-common.dtsi:141 */

			/* node '/soc/timer@40000000/pwm' defined in zephyr/dts/riscv/gd/gd32vf103.dtsi:325 */
			pwm1: pwm {
				compatible = "gd,gd32-pwm";    /* in zephyr/dts/riscv/gd/gd32vf103.dtsi:326 */
				#pwm-cells = < 0x3 >;          /* in zephyr/dts/riscv/gd/gd32vf103.dtsi:328 */
				status = "okay";               /* in zephyr/boards/sipeed/longan_nano/longan_nano-common.dtsi:144 */
				pinctrl-0 = < &pwm1_default >; /* in zephyr/boards/sipeed/longan_nano/longan_nano-common.dtsi:145 */
				pinctrl-names = "default";     /* in zephyr/boards/sipeed/longan_nano/longan_nano-common.dtsi:146 */
				phandle = < 0xd >;             /* in zephyr/boards/sipeed/longan_nano/longan_nano-common.dtsi:54 */
			};
		};

		/* node '/soc/timer@40000400' defined in zephyr/dts/riscv/gd/gd32vf103.dtsi:332 */
		timer2: timer@40000400 {
			compatible = "gd,gd32-timer"; /* in zephyr/dts/riscv/gd/gd32vf103.dtsi:333 */
			reg = < 0x40000400 0x400 >;   /* in zephyr/dts/riscv/gd/gd32vf103.dtsi:334 */
			interrupts = < 0x30 0x0 >;    /* in zephyr/dts/riscv/gd/gd32vf103.dtsi:335 */
			interrupt-names = "global";   /* in zephyr/dts/riscv/gd/gd32vf103.dtsi:336 */
			clocks = < &cctl 0x701 >;     /* in zephyr/dts/riscv/gd/gd32vf103.dtsi:337 */
			resets = < &rctl 0x401 >;     /* in zephyr/dts/riscv/gd/gd32vf103.dtsi:338 */
			channels = < 0x4 >;           /* in zephyr/dts/riscv/gd/gd32vf103.dtsi:339 */
			status = "disabled";          /* in zephyr/dts/riscv/gd/gd32vf103.dtsi:340 */

			/* node '/soc/timer@40000400/pwm' defined in zephyr/dts/riscv/gd/gd32vf103.dtsi:342 */
			pwm {
				compatible = "gd,gd32-pwm"; /* in zephyr/dts/riscv/gd/gd32vf103.dtsi:343 */
				status = "disabled";        /* in zephyr/dts/riscv/gd/gd32vf103.dtsi:344 */
				#pwm-cells = < 0x3 >;       /* in zephyr/dts/riscv/gd/gd32vf103.dtsi:345 */
			};
		};

		/* node '/soc/timer@40000800' defined in zephyr/dts/riscv/gd/gd32vf103.dtsi:349 */
		timer3: timer@40000800 {
			compatible = "gd,gd32-timer"; /* in zephyr/dts/riscv/gd/gd32vf103.dtsi:350 */
			reg = < 0x40000800 0x400 >;   /* in zephyr/dts/riscv/gd/gd32vf103.dtsi:351 */
			interrupts = < 0x31 0x0 >;    /* in zephyr/dts/riscv/gd/gd32vf103.dtsi:352 */
			interrupt-names = "global";   /* in zephyr/dts/riscv/gd/gd32vf103.dtsi:353 */
			clocks = < &cctl 0x702 >;     /* in zephyr/dts/riscv/gd/gd32vf103.dtsi:354 */
			resets = < &rctl 0x402 >;     /* in zephyr/dts/riscv/gd/gd32vf103.dtsi:355 */
			channels = < 0x4 >;           /* in zephyr/dts/riscv/gd/gd32vf103.dtsi:356 */
			status = "disabled";          /* in zephyr/dts/riscv/gd/gd32vf103.dtsi:357 */

			/* node '/soc/timer@40000800/pwm' defined in zephyr/dts/riscv/gd/gd32vf103.dtsi:359 */
			pwm {
				compatible = "gd,gd32-pwm"; /* in zephyr/dts/riscv/gd/gd32vf103.dtsi:360 */
				status = "disabled";        /* in zephyr/dts/riscv/gd/gd32vf103.dtsi:361 */
				#pwm-cells = < 0x3 >;       /* in zephyr/dts/riscv/gd/gd32vf103.dtsi:362 */
			};
		};

		/* node '/soc/timer@40000c00' defined in zephyr/dts/riscv/gd/gd32vf103.dtsi:366 */
		timer4: timer@40000c00 {
			compatible = "gd,gd32-timer"; /* in zephyr/dts/riscv/gd/gd32vf103.dtsi:367 */
			reg = < 0x40000c00 0x400 >;   /* in zephyr/dts/riscv/gd/gd32vf103.dtsi:368 */
			interrupts = < 0x45 0x0 >;    /* in zephyr/dts/riscv/gd/gd32vf103.dtsi:369 */
			interrupt-names = "global";   /* in zephyr/dts/riscv/gd/gd32vf103.dtsi:370 */
			clocks = < &cctl 0x703 >;     /* in zephyr/dts/riscv/gd/gd32vf103.dtsi:371 */
			resets = < &rctl 0x403 >;     /* in zephyr/dts/riscv/gd/gd32vf103.dtsi:372 */
			channels = < 0x4 >;           /* in zephyr/dts/riscv/gd/gd32vf103.dtsi:373 */
			status = "disabled";          /* in zephyr/dts/riscv/gd/gd32vf103.dtsi:374 */

			/* node '/soc/timer@40000c00/pwm' defined in zephyr/dts/riscv/gd/gd32vf103.dtsi:376 */
			pwm {
				compatible = "gd,gd32-pwm"; /* in zephyr/dts/riscv/gd/gd32vf103.dtsi:377 */
				status = "disabled";        /* in zephyr/dts/riscv/gd/gd32vf103.dtsi:378 */
				#pwm-cells = < 0x3 >;       /* in zephyr/dts/riscv/gd/gd32vf103.dtsi:379 */
			};
		};

		/* node '/soc/timer@40001000' defined in zephyr/dts/riscv/gd/gd32vf103.dtsi:383 */
		timer5: timer@40001000 {
			compatible = "gd,gd32-timer"; /* in zephyr/dts/riscv/gd/gd32vf103.dtsi:384 */
			reg = < 0x40001000 0x400 >;   /* in zephyr/dts/riscv/gd/gd32vf103.dtsi:385 */
			interrupts = < 0x49 0x0 >;    /* in zephyr/dts/riscv/gd/gd32vf103.dtsi:386 */
			interrupt-names = "global";   /* in zephyr/dts/riscv/gd/gd32vf103.dtsi:387 */
			clocks = < &cctl 0x704 >;     /* in zephyr/dts/riscv/gd/gd32vf103.dtsi:388 */
			resets = < &rctl 0x404 >;     /* in zephyr/dts/riscv/gd/gd32vf103.dtsi:389 */
			channels = < 0x0 >;           /* in zephyr/dts/riscv/gd/gd32vf103.dtsi:390 */
			status = "disabled";          /* in zephyr/dts/riscv/gd/gd32vf103.dtsi:391 */
		};

		/* node '/soc/timer@40001400' defined in zephyr/dts/riscv/gd/gd32vf103.dtsi:394 */
		timer6: timer@40001400 {
			compatible = "gd,gd32-timer"; /* in zephyr/dts/riscv/gd/gd32vf103.dtsi:395 */
			reg = < 0x40001400 0x400 >;   /* in zephyr/dts/riscv/gd/gd32vf103.dtsi:396 */
			interrupts = < 0x4a 0x0 >;    /* in zephyr/dts/riscv/gd/gd32vf103.dtsi:397 */
			interrupt-names = "global";   /* in zephyr/dts/riscv/gd/gd32vf103.dtsi:398 */
			clocks = < &cctl 0x705 >;     /* in zephyr/dts/riscv/gd/gd32vf103.dtsi:399 */
			resets = < &rctl 0x405 >;     /* in zephyr/dts/riscv/gd/gd32vf103.dtsi:400 */
			channels = < 0x0 >;           /* in zephyr/dts/riscv/gd/gd32vf103.dtsi:401 */
			status = "disabled";          /* in zephyr/dts/riscv/gd/gd32vf103.dtsi:402 */
		};

		/* node '/soc/dma@40020000' defined in zephyr/dts/riscv/gd/gd32vf103.dtsi:405 */
		dma0: dma@40020000 {
			compatible = "gd,gd32-dma"; /* in zephyr/dts/riscv/gd/gd32vf103.dtsi:406 */
			reg = < 0x40020000 0x400 >; /* in zephyr/dts/riscv/gd/gd32vf103.dtsi:407 */
			interrupts = < 0x1e 0x0 >,
			             < 0x1f 0x0 >,
			             < 0x20 0x0 >,
			             < 0x21 0x0 >,
			             < 0x22 0x0 >,
			             < 0x23 0x0 >,
			             < 0x24 0x0 >;  /* in zephyr/dts/riscv/gd/gd32vf103.dtsi:408 */
			clocks = < &cctl 0x500 >;   /* in zephyr/dts/riscv/gd/gd32vf103.dtsi:410 */
			dma-channels = < 0x7 >;     /* in zephyr/dts/riscv/gd/gd32vf103.dtsi:411 */
			gd,mem2mem;                 /* in zephyr/dts/riscv/gd/gd32vf103.dtsi:412 */
			#dma-cells = < 0x2 >;       /* in zephyr/dts/riscv/gd/gd32vf103.dtsi:413 */
			status = "disabled";        /* in zephyr/dts/riscv/gd/gd32vf103.dtsi:414 */
		};

		/* node '/soc/dma@40020400' defined in zephyr/dts/riscv/gd/gd32vf103.dtsi:417 */
		dma1: dma@40020400 {
			compatible = "gd,gd32-dma"; /* in zephyr/dts/riscv/gd/gd32vf103.dtsi:418 */
			reg = < 0x40020400 0x400 >; /* in zephyr/dts/riscv/gd/gd32vf103.dtsi:419 */
			interrupts = < 0x4b 0x0 >,
			             < 0x4c 0x0 >,
			             < 0x4d 0x0 >,
			             < 0x4e 0x0 >,
			             < 0x4f 0x0 >;  /* in zephyr/dts/riscv/gd/gd32vf103.dtsi:420 */
			clocks = < &cctl 0x501 >;   /* in zephyr/dts/riscv/gd/gd32vf103.dtsi:422 */
			dma-channels = < 0x5 >;     /* in zephyr/dts/riscv/gd/gd32vf103.dtsi:423 */
			gd,mem2mem;                 /* in zephyr/dts/riscv/gd/gd32vf103.dtsi:424 */
			#dma-cells = < 0x2 >;       /* in zephyr/dts/riscv/gd/gd32vf103.dtsi:425 */
			status = "disabled";        /* in zephyr/dts/riscv/gd/gd32vf103.dtsi:426 */
		};
	};

	/* node '/chosen' defined in zephyr/boards/sipeed/longan_nano/longan_nano-common.dtsi:11 */
	chosen {
		zephyr,console = &usart0;    /* in zephyr/boards/sipeed/longan_nano/longan_nano-common.dtsi:12 */
		zephyr,shell-uart = &usart0; /* in zephyr/boards/sipeed/longan_nano/longan_nano-common.dtsi:13 */
		zephyr,sram = &sram0;        /* in zephyr/boards/sipeed/longan_nano/longan_nano-common.dtsi:14 */
		zephyr,flash = &flash0;      /* in zephyr/boards/sipeed/longan_nano/longan_nano-common.dtsi:15 */
		zephyr,display = &lcd0;      /* in zephyr/boards/sipeed/longan_nano/longan_nano-common.dtsi:16 */
		sdhc0 = &sdhc0;              /* in zephyr/boards/sipeed/longan_nano/longan_nano-common.dtsi:17 */
	};

	/* node '/leds' defined in zephyr/boards/sipeed/longan_nano/longan_nano-common.dtsi:20 */
	leds {
		compatible = "gpio-leds"; /* in zephyr/boards/sipeed/longan_nano/longan_nano-common.dtsi:21 */

		/* node '/leds/led_red' defined in zephyr/boards/sipeed/longan_nano/longan_nano-common.dtsi:23 */
		led_red: led_red {
			gpios = < &gpioc 0xd 0x1 >; /* in zephyr/boards/sipeed/longan_nano/longan_nano-common.dtsi:24 */
			label = "LED_R";            /* in zephyr/boards/sipeed/longan_nano/longan_nano-common.dtsi:25 */
		};

		/* node '/leds/led_green' defined in zephyr/boards/sipeed/longan_nano/longan_nano-common.dtsi:28 */
		led_green: led_green {
			gpios = < &gpioa 0x1 0x1 >; /* in zephyr/boards/sipeed/longan_nano/longan_nano-common.dtsi:29 */
			label = "LED_G";            /* in zephyr/boards/sipeed/longan_nano/longan_nano-common.dtsi:30 */
		};

		/* node '/leds/led_blue' defined in zephyr/boards/sipeed/longan_nano/longan_nano-common.dtsi:33 */
		led_blue: led_blue {
			gpios = < &gpioa 0x2 0x1 >; /* in zephyr/boards/sipeed/longan_nano/longan_nano-common.dtsi:34 */
			label = "LED_B";            /* in zephyr/boards/sipeed/longan_nano/longan_nano-common.dtsi:35 */
		};
	};

	/* node '/gpio_keys' defined in zephyr/boards/sipeed/longan_nano/longan_nano-common.dtsi:39 */
	gpio_keys {
		compatible = "gpio-keys"; /* in zephyr/boards/sipeed/longan_nano/longan_nano-common.dtsi:40 */

		/* node '/gpio_keys/button_boot0' defined in zephyr/boards/sipeed/longan_nano/longan_nano-common.dtsi:42 */
		button_boot0: button_boot0 {
			label = "BUTTON_BOOT0";     /* in zephyr/boards/sipeed/longan_nano/longan_nano-common.dtsi:43 */
			gpios = < &gpioa 0x8 0x0 >; /* in zephyr/boards/sipeed/longan_nano/longan_nano-common.dtsi:44 */
			zephyr,code = < 0xb >;      /* in zephyr/boards/sipeed/longan_nano/longan_nano-common.dtsi:45 */
		};
	};

	/* node '/pwmleds' defined in zephyr/boards/sipeed/longan_nano/longan_nano-common.dtsi:49 */
	pwmleds {
		compatible = "pwm-leds"; /* in zephyr/boards/sipeed/longan_nano/longan_nano-common.dtsi:50 */

		/* node '/pwmleds/pwm_led_green' defined in zephyr/boards/sipeed/longan_nano/longan_nano-common.dtsi:53 */
		pwm_led_green: pwm_led_green {
			pwms = < &pwm1 0x1 0x1312d00 0x0 >; /* in zephyr/boards/sipeed/longan_nano/longan_nano-common.dtsi:54 */
			label = "PWM_LED_G";                /* in zephyr/boards/sipeed/longan_nano/longan_nano-common.dtsi:55 */
		};

		/* node '/pwmleds/pwm_led_blue' defined in zephyr/boards/sipeed/longan_nano/longan_nano-common.dtsi:59 */
		pwm_led_blue: pwm_led_blue {
			pwms = < &pwm1 0x2 0x1312d00 0x0 >; /* in zephyr/boards/sipeed/longan_nano/longan_nano-common.dtsi:60 */
			label = "PWM_LED_B";                /* in zephyr/boards/sipeed/longan_nano/longan_nano-common.dtsi:61 */
		};
	};

	/* node '/aliases' defined in zephyr/boards/sipeed/longan_nano/longan_nano-common.dtsi:65 */
	aliases {
		led0 = &led_red;           /* in zephyr/boards/sipeed/longan_nano/longan_nano-common.dtsi:66 */
		led1 = &led_green;         /* in zephyr/boards/sipeed/longan_nano/longan_nano-common.dtsi:67 */
		led2 = &led_blue;          /* in zephyr/boards/sipeed/longan_nano/longan_nano-common.dtsi:68 */
		pwm-led0 = &pwm_led_green; /* in zephyr/boards/sipeed/longan_nano/longan_nano-common.dtsi:69 */
		pwm-led1 = &pwm_led_blue;  /* in zephyr/boards/sipeed/longan_nano/longan_nano-common.dtsi:70 */
		sw0 = &button_boot0;       /* in zephyr/boards/sipeed/longan_nano/longan_nano-common.dtsi:71 */
		watchdog0 = &fwdgt;        /* in zephyr/boards/sipeed/longan_nano/longan_nano-common.dtsi:72 */
	};

	/* node '/mipi_dbi' defined in zephyr/boards/sipeed/longan_nano/longan_nano-common.dtsi:75 */
	mipi_dbi {
		compatible = "zephyr,mipi-dbi-spi"; /* in zephyr/boards/sipeed/longan_nano/longan_nano-common.dtsi:76 */
		reset-gpios = < &gpiob 0x1 0x1 >;   /* in zephyr/boards/sipeed/longan_nano/longan_nano-common.dtsi:77 */
		dc-gpios = < &gpiob 0x0 0x0 >;      /* in zephyr/boards/sipeed/longan_nano/longan_nano-common.dtsi:78 */
		spi-dev = < &spi0 >;                /* in zephyr/boards/sipeed/longan_nano/longan_nano-common.dtsi:79 */
		write-only;                         /* in zephyr/boards/sipeed/longan_nano/longan_nano-common.dtsi:80 */
		#address-cells = < 0x1 >;           /* in zephyr/boards/sipeed/longan_nano/longan_nano-common.dtsi:81 */
		#size-cells = < 0x0 >;              /* in zephyr/boards/sipeed/longan_nano/longan_nano-common.dtsi:82 */

		/* node '/mipi_dbi/lcd@0' defined in zephyr/boards/sipeed/longan_nano/longan_nano-common.dtsi:87 */
		lcd0: lcd@0 {
			compatible = "sitronix,st7735r";                                /* in zephyr/boards/sipeed/longan_nano/longan_nano-common.dtsi:88 */
			reg = < 0x0 >;                                                  /* in zephyr/boards/sipeed/longan_nano/longan_nano-common.dtsi:89 */
			status = "okay";                                                /* in zephyr/boards/sipeed/longan_nano/longan_nano-common.dtsi:90 */
			width = < 0xa0 >;                                               /* in zephyr/boards/sipeed/longan_nano/longan_nano-common.dtsi:91 */
			height = < 0x50 >;                                              /* in zephyr/boards/sipeed/longan_nano/longan_nano-common.dtsi:92 */
			inversion-on;                                                   /* in zephyr/boards/sipeed/longan_nano/longan_nano-common.dtsi:93 */
			rgb-is-inverted;                                                /* in zephyr/boards/sipeed/longan_nano/longan_nano-common.dtsi:94 */
			x-offset = < 0x1 >;                                             /* in zephyr/boards/sipeed/longan_nano/longan_nano-common.dtsi:95 */
			y-offset = < 0x1a >;                                            /* in zephyr/boards/sipeed/longan_nano/longan_nano-common.dtsi:96 */
			pwctr1 = [ 62 02 04 ];                                          /* in zephyr/boards/sipeed/longan_nano/longan_nano-common.dtsi:97 */
			pwctr2 = [ C0 ];                                                /* in zephyr/boards/sipeed/longan_nano/longan_nano-common.dtsi:98 */
			pwctr3 = [ 0D 00 ];                                             /* in zephyr/boards/sipeed/longan_nano/longan_nano-common.dtsi:99 */
			pwctr4 = [ 8D 6A ];                                             /* in zephyr/boards/sipeed/longan_nano/longan_nano-common.dtsi:100 */
			pwctr5 = [ 8D EE ];                                             /* in zephyr/boards/sipeed/longan_nano/longan_nano-common.dtsi:101 */
			invctr = < 0x3 >;                                               /* in zephyr/boards/sipeed/longan_nano/longan_nano-common.dtsi:102 */
			frmctr1 = [ 05 3A 3A ];                                         /* in zephyr/boards/sipeed/longan_nano/longan_nano-common.dtsi:103 */
			frmctr2 = [ 05 3A 3A ];                                         /* in zephyr/boards/sipeed/longan_nano/longan_nano-common.dtsi:104 */
			frmctr3 = [ 05 3A 3A 05 3A 3A ];                                /* in zephyr/boards/sipeed/longan_nano/longan_nano-common.dtsi:105 */
			vmctr1 = < 0xe >;                                               /* in zephyr/boards/sipeed/longan_nano/longan_nano-common.dtsi:106 */
			gamctrp1 = [ 10 0E 02 03 0E 07 02 07 0A 12 27 37 00 0D 0E 10 ]; /* in zephyr/boards/sipeed/longan_nano/longan_nano-common.dtsi:107 */
			gamctrn1 = [ 10 0E 03 03 0F 06 02 08 0A 13 26 36 00 0D 0E 10 ]; /* in zephyr/boards/sipeed/longan_nano/longan_nano-common.dtsi:108 */
			colmod = < 0x5 >;                                               /* in zephyr/boards/sipeed/longan_nano/longan_nano-common.dtsi:109 */
			madctl = < 0x78 >;                                              /* in zephyr/boards/sipeed/longan_nano/longan_nano-common.dtsi:110 */
			caset = [ 00 01 00 A0 ];                                        /* in zephyr/boards/sipeed/longan_nano/longan_nano-common.dtsi:111 */
			raset = [ 00 1A 00 69 ];                                        /* in zephyr/boards/sipeed/longan_nano/longan_nano-common.dtsi:112 */
			mipi-mode = "MIPI_DBI_MODE_SPI_4WIRE";                          /* in zephyr/boards/sipeed/longan_nano/longan_nano-common.dtsi:114 */
			mipi-max-frequency = < 0x3d0900 >;                              /* in zephyr/boards/sipeed/longan_nano/longan_nano-common.dtsi:115 */
		};
	};
};
